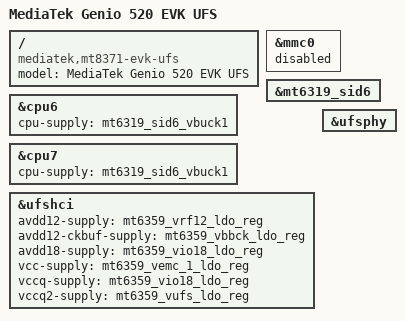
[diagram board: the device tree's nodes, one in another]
// SPDX-License-Identifier: (GPL-2.0 OR MIT)
/*
 * Copyright (c) 2025 Collabora Ltd.
 * Author: Louis-Alexis Eyraud <louisalexis.eyraud@collabora.com>
 */
/dts-v1/;
#include "mt8189.dtsi"
#include "mt8391-genio-common.dtsi"

/ {
	model = "MediaTek Genio 520 EVK UFS";
	compatible = "mediatek,mt8371-evk-ufs", "mediatek,mt8371",
		     "mediatek,mt8189";
};

&cpu6 {
	cpu-supply = <&mt6319_sid6_vbuck1>;
};

&cpu7 {
	cpu-supply = <&mt6319_sid6_vbuck1>;
};

&mmc0 {
	status = "disabled";
};

&mt6319_sid6 {
	status = "okay";
};

&ufshci {
	status = "okay";
	avdd12-supply = <&mt6359_vrf12_ldo_reg>;
	avdd12-ckbuf-supply = <&mt6359_vbbck_ldo_reg>;
	avdd18-supply = <&mt6359_vio18_ldo_reg>;
	vcc-supply = <&mt6359_vemc_1_ldo_reg>;
	vccq-supply = <&mt6359_vio18_ldo_reg>;
	vccq2-supply = <&mt6359_vufs_ldo_reg>;
};

&ufsphy {
	status = "okay";
};
